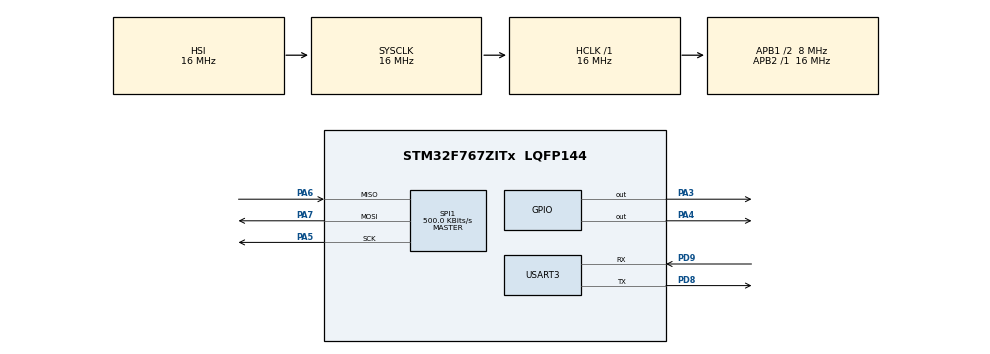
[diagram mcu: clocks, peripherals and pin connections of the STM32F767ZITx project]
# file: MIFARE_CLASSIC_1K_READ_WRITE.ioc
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Mcu.Family=STM32F7
Mcu.Name=STM32F767ZITx
Mcu.Package=LQFP144
NVIC.PriorityGroup=NVIC_PRIORITYGROUP_4
NVIC.USART3_IRQn=true\:0\:0\:false\:false\:true\:true\:true\:true
PA13.Mode=Serial_Wire
PA13.Signal=SYS_JTMS-SWDIO
PA14.Mode=Serial_Wire
PA14.Signal=SYS_JTCK-SWCLK
PA3.PinState=GPIO_PIN_SET
PA3.Signal=GPIO_Output
PA4.PinState=GPIO_PIN_SET
PA4.Signal=GPIO_Output
PA5.Mode=Full_Duplex_Master
PA5.Signal=SPI1_SCK
PA6.Mode=Full_Duplex_Master
PA6.Signal=SPI1_MISO
PA7.Mode=Full_Duplex_Master
PA7.Signal=SPI1_MOSI
PD8.Mode=Asynchronous
PD8.Signal=USART3_TX
PD9.Mode=Asynchronous
PD9.Signal=USART3_RX
PH0/OSC_IN.Mode=HSE-External-Clock-Source
PH0/OSC_IN.Signal=RCC_OSC_IN
PH1/OSC_OUT.Mode=HSE-External-Clock-Source
PH1/OSC_OUT.Signal=RCC_OSC_OUT
ProjectManager.HeapSize=0x200
ProjectManager.StackSize=0x400
ProjectManager.TargetToolchain=STM32CubeIDE
RCC.48MHZClocksFreq_Value=24000000
RCC.AHBFreq_Value=16000000
RCC.APB1CLKDivider=RCC_HCLK_DIV2
RCC.APB1Freq_Value=8000000
RCC.APB1TimFreq_Value=16000000
RCC.APB2Freq_Value=16000000
RCC.APB2TimFreq_Value=16000000
RCC.CortexFreq_Value=16000000
RCC.HCLKFreq_Value=16000000
RCC.HSE_VALUE=16000000
RCC.HSI_VALUE=16000000
RCC.LSE_VALUE=32768
RCC.PLLMUL=RCC_PLL_MUL9
RCC.PRESCALERUSB=RCC_USBCLKSOURCE_PLL_DIV1_5
RCC.SYSCLKFreq_VALUE=16000000
RCC.SYSCLKSourceVirtual=RCC_SYSCLKSOURCE_PLLCLK
RCC.USBFreq_Value=96000000
RCC.VCOOutputFreq_Value=192000000
SPI1.BaudRatePrescaler=SPI_BAUDRATEPRESCALER_32
SPI1.CalculateBaudRate=500.0 KBits/s
SPI1.DataSize=SPI_DATASIZE_8BIT
SPI1.Direction=SPI_DIRECTION_2LINES
SPI1.Mode=SPI_MODE_MASTER
SPI1.VirtualType=VM_MASTER
USART3.VirtualMode-Asynchronous=VM_ASYNC
board=NUCLEO-F767ZI

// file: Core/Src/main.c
/* USER CODE BEGIN Header */
/**
  ******************************************************************************
  * @file           : main.c
  * @brief          : Main program body
  ******************************************************************************
  * @attention
  *
  * Copyright (c) 2026 STMicroelectronics.
  * All rights reserved.
  *
  * This software is licensed under terms that can be found in the LICENSE file
  * in the root directory of this software component.
  * If no LICENSE file comes with this software, it is provided AS-IS.
  *
  ******************************************************************************
  */
/* USER CODE END Header */
#include "main.h"

/* USER CODE BEGIN Includes */
#include "rfid_cli.h"
/* USER CODE END Includes */

SPI_HandleTypeDef hspi1;

UART_HandleTypeDef huart3;

void SystemClock_Config(void);
static void MX_GPIO_Init(void);
static void MX_SPI1_Init(void);
static void MX_USART3_UART_Init(void);

int main(void)
{

  /* MCU Configuration--------------------------------------------------------*/

  /* Reset of all peripherals, Initializes the Flash interface and the Systick. */
  HAL_Init();

  /* Configure the system clock */
  SystemClock_Config();

  /* Initialize all configured peripherals */
  MX_GPIO_Init();
  MX_SPI1_Init();
  MX_USART3_UART_Init();
  /* USER CODE BEGIN 2 */
  rfid_cli_t cli = {0};
    cli.huart = &huart3;

    cli.rc522.hspi = &hspi1;
    cli.rc522.cs_port = GPIOA;
    cli.rc522.cs_pin  = GPIO_PIN_4;   // CS = PA4
    cli.rc522.rst_port = GPIOA;
    cli.rc522.rst_pin  = GPIO_PIN_3;  // RST = PA3

    RFID_CLI_Run(&cli);
  /* USER CODE END 2 */

  /* Infinite loop */
  while (1)
  {

  }
}

void SystemClock_Config(void)
{
  RCC_OscInitTypeDef RCC_OscInitStruct = {0};
  RCC_ClkInitTypeDef RCC_ClkInitStruct = {0};

  /** Configure the main internal regulator output voltage
  */
  __HAL_RCC_PWR_CLK_ENABLE();
  __HAL_PWR_VOLTAGESCALING_CONFIG(PWR_REGULATOR_VOLTAGE_SCALE3);

  /** Initializes the RCC Oscillators according to the specified parameters
  * in the RCC_OscInitTypeDef structure.
  */
  RCC_OscInitStruct.OscillatorType = RCC_OSCILLATORTYPE_HSI;
  RCC_OscInitStruct.HSIState = RCC_HSI_ON;
  RCC_OscInitStruct.HSICalibrationValue = RCC_HSICALIBRATION_DEFAULT;
  RCC_OscInitStruct.PLL.PLLState = RCC_PLL_NONE;
  if (HAL_RCC_OscConfig(&RCC_OscInitStruct) != HAL_OK)
  {
    Error_Handler();
  }

  /** Initializes the CPU, AHB and APB buses clocks
  */
  RCC_ClkInitStruct.ClockType = RCC_CLOCKTYPE_HCLK|RCC_CLOCKTYPE_SYSCLK
                              |RCC_CLOCKTYPE_PCLK1|RCC_CLOCKTYPE_PCLK2;
  RCC_ClkInitStruct.SYSCLKSource = RCC_SYSCLKSOURCE_HSI;
  RCC_ClkInitStruct.AHBCLKDivider = RCC_SYSCLK_DIV1;
  RCC_ClkInitStruct.APB1CLKDivider = RCC_HCLK_DIV2;
  RCC_ClkInitStruct.APB2CLKDivider = RCC_HCLK_DIV1;

  if (HAL_RCC_ClockConfig(&RCC_ClkInitStruct, FLASH_LATENCY_0) != HAL_OK)
  {
    Error_Handler();
  }
}

static void MX_SPI1_Init(void)
{

  /* SPI1 parameter configuration*/
  hspi1.Instance = SPI1;
  hspi1.Init.Mode = SPI_MODE_MASTER;
  hspi1.Init.Direction = SPI_DIRECTION_2LINES;
  hspi1.Init.DataSize = SPI_DATASIZE_8BIT;
  hspi1.Init.CLKPolarity = SPI_POLARITY_LOW;
  hspi1.Init.CLKPhase = SPI_PHASE_1EDGE;
  hspi1.Init.NSS = SPI_NSS_SOFT;
  hspi1.Init.BaudRatePrescaler = SPI_BAUDRATEPRESCALER_32;
  hspi1.Init.FirstBit = SPI_FIRSTBIT_MSB;
  hspi1.Init.TIMode = SPI_TIMODE_DISABLE;
  hspi1.Init.CRCCalculation = SPI_CRCCALCULATION_DISABLE;
  hspi1.Init.CRCPolynomial = 7;
  hspi1.Init.CRCLength = SPI_CRC_LENGTH_DATASIZE;
  hspi1.Init.NSSPMode = SPI_NSS_PULSE_ENABLE;
  if (HAL_SPI_Init(&hspi1) != HAL_OK)
  {
    Error_Handler();
  }

}

static void MX_USART3_UART_Init(void)
{

  huart3.Instance = USART3;
  huart3.Init.BaudRate = 115200;
  huart3.Init.WordLength = UART_WORDLENGTH_8B;
  huart3.Init.StopBits = UART_STOPBITS_1;
  huart3.Init.Parity = UART_PARITY_NONE;
  huart3.Init.Mode = UART_MODE_TX_RX;
  huart3.Init.HwFlowCtl = UART_HWCONTROL_NONE;
  huart3.Init.OverSampling = UART_OVERSAMPLING_16;
  huart3.Init.OneBitSampling = UART_ONE_BIT_SAMPLE_DISABLE;
  huart3.AdvancedInit.AdvFeatureInit = UART_ADVFEATURE_NO_INIT;
  if (HAL_UART_Init(&huart3) != HAL_OK)
  {
    Error_Handler();
  }

}

static void MX_GPIO_Init(void)
{
  GPIO_InitTypeDef GPIO_InitStruct = {0};

  /* GPIO Ports Clock Enable */
  __HAL_RCC_GPIOH_CLK_ENABLE();
  __HAL_RCC_GPIOA_CLK_ENABLE();
  __HAL_RCC_GPIOD_CLK_ENABLE();

  /*Configure GPIO pin Output Level */
  HAL_GPIO_WritePin(GPIOA, GPIO_PIN_3|GPIO_PIN_4, GPIO_PIN_SET);

  /*Configure GPIO pins : PA3 PA4 */
  GPIO_InitStruct.Pin = GPIO_PIN_3|GPIO_PIN_4;
  GPIO_InitStruct.Mode = GPIO_MODE_OUTPUT_PP;
  GPIO_InitStruct.Pull = GPIO_NOPULL;
  GPIO_InitStruct.Speed = GPIO_SPEED_FREQ_LOW;
  HAL_GPIO_Init(GPIOA, &GPIO_InitStruct);

}

void Error_Handler(void)
{
  __disable_irq();
  while (1)
  {
  }
}
